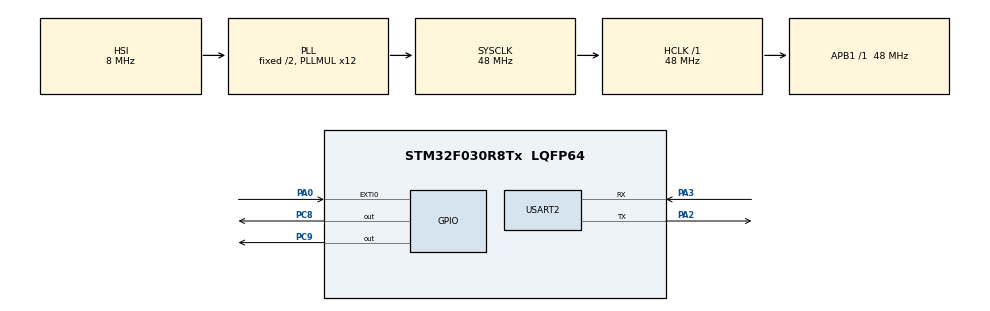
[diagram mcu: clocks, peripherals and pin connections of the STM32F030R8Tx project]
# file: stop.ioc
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Mcu.Family=STM32F0
PC8.Signal=GPIO_Output
RCC.SYSCLKSource=RCC_SYSCLKSOURCE_PLLCLK
ProjectManager.StackSize=0x400
PA3.Mode=Asynchronous
ProjectManager.TargetToolchain=STM32CubeIDE
RCC.HCLKFreq_Value=48000000
RCC.AHBFreq_Value=48000000
PF0-OSC_IN.Mode=HSE-External-Oscillator
board=STM32F0308-DISCO
USART2.VirtualMode-Asynchronous=VM_ASYNC
RCC.PLLMUL=RCC_PLL_MUL12
Mcu.Name=STM32F030R8Tx
PA2.Signal=USART2_TX
PA0.Signal=GPXTI0
RCC.SYSCLKFreq_VALUE=48000000
Mcu.Package=LQFP64
ProjectManager.HeapSize=0x200
RCC.APB1TimFreq_Value=48000000
PA2.Mode=Asynchronous
PC9.Signal=GPIO_Output
PF0-OSC_IN.Signal=RCC_OSC_IN
PF1-OSC_OUT.Mode=HSE-External-Oscillator
RCC.APB1Freq_Value=48000000
PF1-OSC_OUT.Signal=RCC_OSC_OUT
PA3.Signal=USART2_RX
NVIC.EXTI0_1_IRQn=true\:0\:0\:false\:false\:true\:true\:true

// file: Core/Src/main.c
/* USER CODE BEGIN Header */
/**
  ******************************************************************************
  * @file           : main.c
  * @brief          : Main program body
  ******************************************************************************
  * @attention
  *
  * <h2><center>&copy; Copyright (c) 2021 STMicroelectronics.
  * All rights reserved.</center></h2>
  *
  * This software component is licensed by ST under BSD 3-Clause license,
  * the "License"; You may not use this file except in compliance with the
  * License. You may obtain a copy of the License at:
  *                        opensource.org/licenses/BSD-3-Clause
  *
  ******************************************************************************
  */
/* USER CODE END Header */
#include "main.h"

UART_HandleTypeDef huart2;

void SystemClock_Config(void);
static void MX_GPIO_Init(void);
static void MX_USART2_UART_Init(void);

int main(void)
{

  /* MCU Configuration--------------------------------------------------------*/

  /* Reset of all peripherals, Initializes the Flash interface and the Systick. */
  HAL_Init();

  /* Configure the system clock */
  SystemClock_Config();

  /* Initialize all configured peripherals */
  MX_GPIO_Init();
  MX_USART2_UART_Init();
  /* USER CODE BEGIN 2 */
  HAL_UART_Transmit(&huart2, (uint8_t *)"going to stop\n", 14, 1000);
  /* USER CODE END 2 */
  for(int i=0; i<20; i++)
  {
	  HAL_GPIO_TogglePin(GPIOC, GPIO_PIN_8);
	  HAL_Delay(250);
  }
  HAL_SuspendTick();
  HAL_PWR_EnterSTOPMode(PWR_LOWPOWERREGULATOR_ON, PWR_STOPENTRY_WFI);

  SystemClock_Config();
  HAL_ResumeTick();
  HAL_UART_Transmit(&huart2, (uint8_t *)"going to wake\n", 14, 1000);
  for(int i=0; i<20; i++)
  {
	  HAL_GPIO_TogglePin(GPIOC, GPIO_PIN_9);
	  HAL_Delay(250);
  }
  /* Infinite loop */
  while (1)
  {

  }
}

void SystemClock_Config(void)
{
  RCC_OscInitTypeDef RCC_OscInitStruct = {0};
  RCC_ClkInitTypeDef RCC_ClkInitStruct = {0};

  /** Initializes the RCC Oscillators according to the specified parameters
  * in the RCC_OscInitTypeDef structure.
  */
  RCC_OscInitStruct.OscillatorType = RCC_OSCILLATORTYPE_HSI;
  RCC_OscInitStruct.HSIState = RCC_HSI_ON;
  RCC_OscInitStruct.HSICalibrationValue = RCC_HSICALIBRATION_DEFAULT;
  RCC_OscInitStruct.PLL.PLLState = RCC_PLL_ON;
  RCC_OscInitStruct.PLL.PLLSource = RCC_PLLSOURCE_HSI;
  RCC_OscInitStruct.PLL.PLLMUL = RCC_PLL_MUL12;
  RCC_OscInitStruct.PLL.PREDIV = RCC_PREDIV_DIV1;
  if (HAL_RCC_OscConfig(&RCC_OscInitStruct) != HAL_OK)
  {
    Error_Handler();
  }
  /** Initializes the CPU, AHB and APB buses clocks
  */
  RCC_ClkInitStruct.ClockType = RCC_CLOCKTYPE_HCLK|RCC_CLOCKTYPE_SYSCLK
                              |RCC_CLOCKTYPE_PCLK1;
  RCC_ClkInitStruct.SYSCLKSource = RCC_SYSCLKSOURCE_PLLCLK;
  RCC_ClkInitStruct.AHBCLKDivider = RCC_SYSCLK_DIV1;
  RCC_ClkInitStruct.APB1CLKDivider = RCC_HCLK_DIV1;

  if (HAL_RCC_ClockConfig(&RCC_ClkInitStruct, FLASH_LATENCY_1) != HAL_OK)
  {
    Error_Handler();
  }
}

static void MX_USART2_UART_Init(void)
{

  huart2.Instance = USART2;
  huart2.Init.BaudRate = 38400;
  huart2.Init.WordLength = UART_WORDLENGTH_8B;
  huart2.Init.StopBits = UART_STOPBITS_1;
  huart2.Init.Parity = UART_PARITY_NONE;
  huart2.Init.Mode = UART_MODE_TX_RX;
  huart2.Init.HwFlowCtl = UART_HWCONTROL_NONE;
  huart2.Init.OverSampling = UART_OVERSAMPLING_16;
  huart2.Init.OneBitSampling = UART_ONE_BIT_SAMPLE_DISABLE;
  huart2.AdvancedInit.AdvFeatureInit = UART_ADVFEATURE_NO_INIT;
  if (HAL_UART_Init(&huart2) != HAL_OK)
  {
    Error_Handler();
  }

}

static void MX_GPIO_Init(void)
{
  GPIO_InitTypeDef GPIO_InitStruct = {0};

  /* GPIO Ports Clock Enable */
  __HAL_RCC_GPIOF_CLK_ENABLE();
  __HAL_RCC_GPIOA_CLK_ENABLE();
  __HAL_RCC_GPIOC_CLK_ENABLE();

  /*Configure GPIO pin Output Level */
  HAL_GPIO_WritePin(GPIOC, GPIO_PIN_8|GPIO_PIN_9, GPIO_PIN_RESET);

  /*Configure GPIO pin : PA0 */
  GPIO_InitStruct.Pin = GPIO_PIN_0;
  GPIO_InitStruct.Mode = GPIO_MODE_IT_RISING;
  GPIO_InitStruct.Pull = GPIO_NOPULL;
  HAL_GPIO_Init(GPIOA, &GPIO_InitStruct);

  /*Configure GPIO pins : PC8 PC9 */
  GPIO_InitStruct.Pin = GPIO_PIN_8|GPIO_PIN_9;
  GPIO_InitStruct.Mode = GPIO_MODE_OUTPUT_PP;
  GPIO_InitStruct.Pull = GPIO_NOPULL;
  GPIO_InitStruct.Speed = GPIO_SPEED_FREQ_LOW;
  HAL_GPIO_Init(GPIOC, &GPIO_InitStruct);

  /* EXTI interrupt init*/
  HAL_NVIC_SetPriority(EXTI0_1_IRQn, 0, 0);
  HAL_NVIC_EnableIRQ(EXTI0_1_IRQn);

}

void Error_Handler(void)
{
  __disable_irq();
  while (1)
  {
  }
}

/************************ (C) COPYRIGHT STMicroelectronics *****END OF FILE****/
